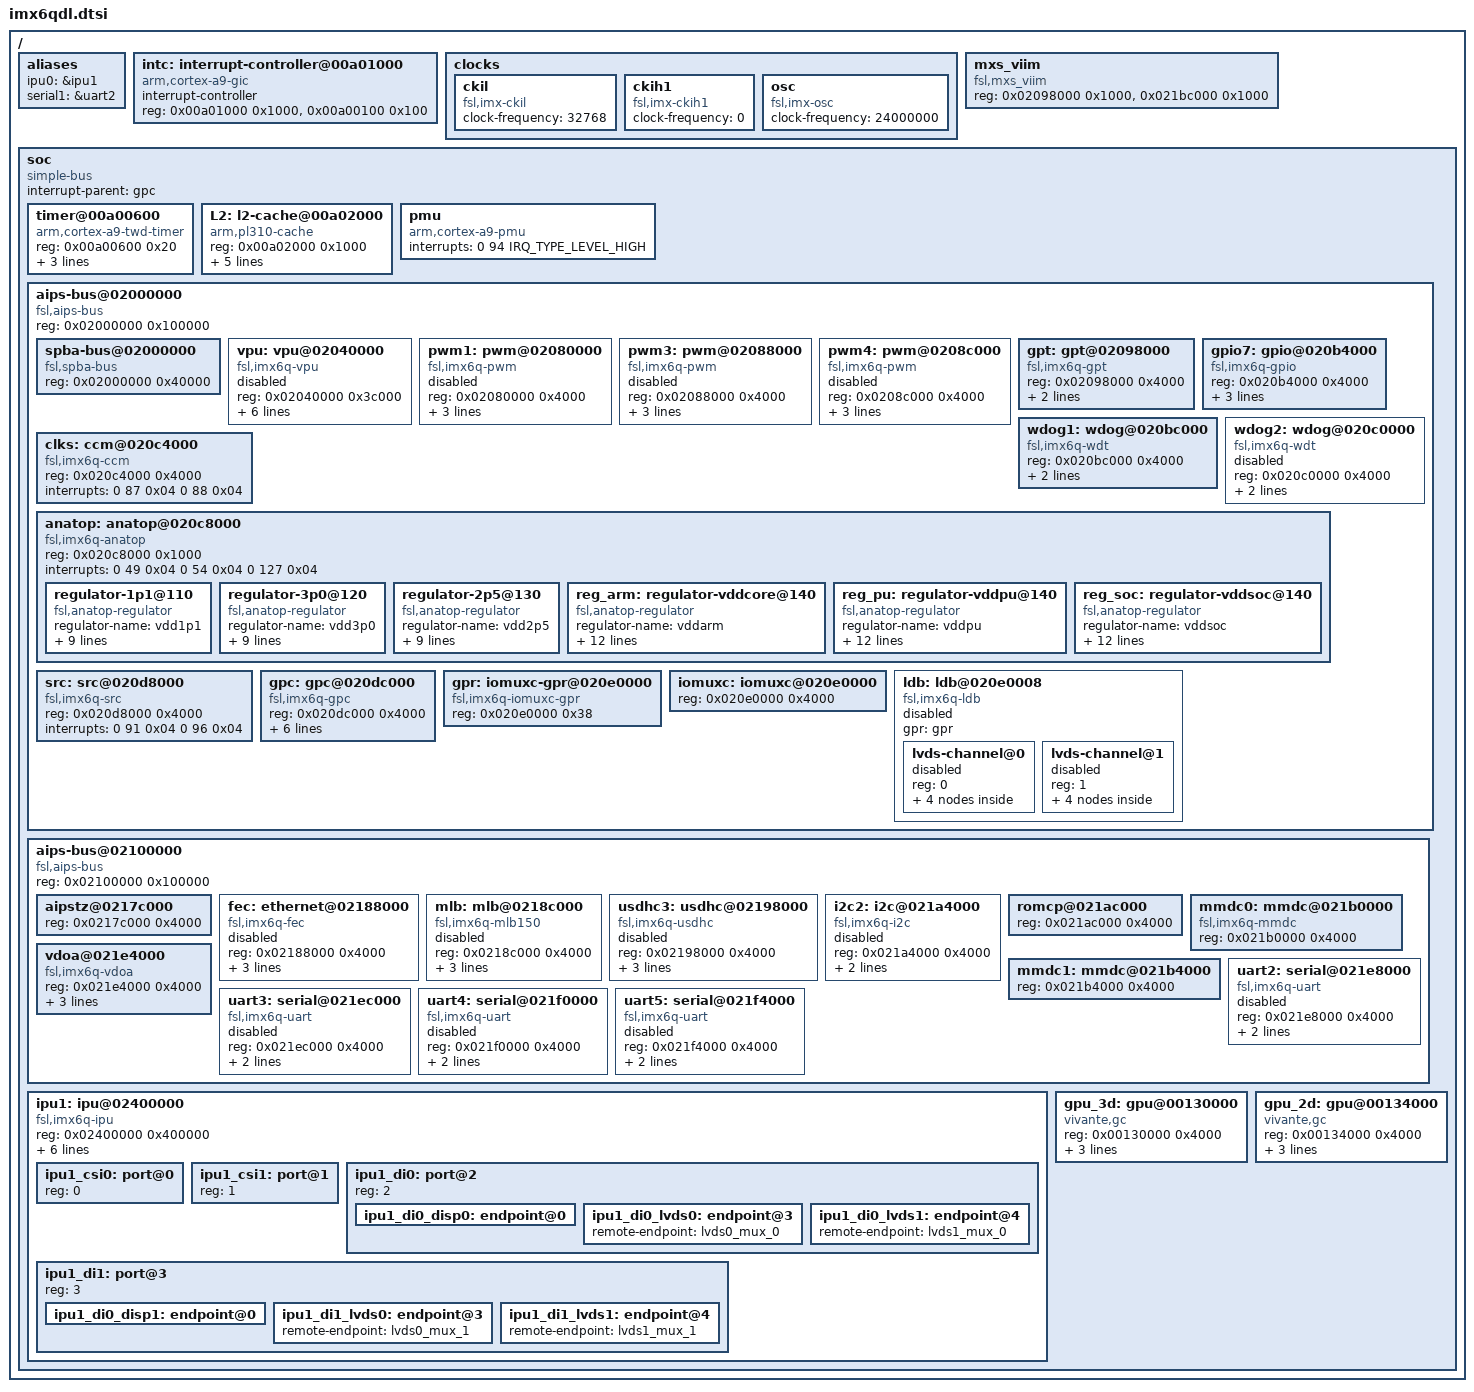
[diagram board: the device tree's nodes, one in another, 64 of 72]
/*
 * Copyright 2011 Freescale Semiconductor, Inc.
 * Copyright 2011 Linaro Ltd.
 *
 * The code contained herein is licensed under the GNU General Public
 * License. You may obtain a copy of the GNU General Public License
 * Version 2 or later at the following locations:
 *
 * http://www.opensource.org/licenses/gpl-license.html
 * http://www.gnu.org/copyleft/gpl.html
 */

#include "skeleton.dtsi"
#include <dt-bindings/gpio/gpio.h>
#include <dt-bindings/interrupt-controller/arm-gic.h>
#include <dt-bindings/clock/imx6qdl-clock.h>

/ {
	aliases {
		/* flexcan0 = &flexcan1; */
		/* flexcan1 = &flexcan2; */
		/* gpio0 = &gpio1; */
		/* gpio1 = &gpio2; */
		/* gpio2 = &gpio3; */
		/* gpio3 = &gpio4; */
		/* gpio4 = &gpio5; */
		/* gpio5 = &gpio6; */
		/* gpio6 = &gpio7; */
		ipu0 = &ipu1;
		/* serial0 = &uart1; */
		serial1 = &uart2;
		/* serial2 = &uart3; */
		/* serial3 = &uart4; */
		/* serial4 = &uart5; */
		/* usbphy0 = &usbphy1; */
		/* usbphy1 = &usbphy2; */
	};

	intc: interrupt-controller@00a01000 {
		compatible = "arm,cortex-a9-gic";
		#interrupt-cells = <3>;
		#address-cells = <1>;
		#size-cells = <1>;
		interrupt-controller;
		reg = <0x00a01000 0x1000>,
		      <0x00a00100 0x100>;
	};

	clocks {
		#address-cells = <1>;
		#size-cells = <0>;

		ckil {
			compatible = "fsl,imx-ckil", "fixed-clock";
			clock-frequency = <32768>;
		};

		ckih1 {
			compatible = "fsl,imx-ckih1", "fixed-clock";
			clock-frequency = <0>;
		};

		osc {
			compatible = "fsl,imx-osc", "fixed-clock";
			clock-frequency = <24000000>;
		};
	};

//	pu_dummy: pudummy_reg {
//		compatible = "fsl,imx6-dummy-pureg"; /* only used in ldo-bypass */
//	};

	mxs_viim {
		compatible = "fsl,mxs_viim";
		reg = <0x02098000 0x1000>, /* GPT base */
		      <0x021bc000 0x1000>; /* OCOTP base */
	};

	soc {
		#address-cells = <1>;
		#size-cells = <1>;
		compatible = "simple-bus";
		interrupt-parent = <&gpc>;
		ranges;

		/* caam_sm: caam-sm@00100000 { */
		/* 	compatible = "fsl,imx6q-caam-sm"; */
		/* 	reg = <0x00100000 0x3fff>; */
		/* }; */

	//	dma_apbh: dma-apbh@00110000 {
	//		compatible = "fsl,imx6q-dma-apbh", "fsl,imx28-dma-apbh";
	//		reg = <0x00110000 0x2000>;
	//		interrupts = <0 13 0x04>, <0 13 0x04>, <0 13 0x04>, <0 13 0x04>;
	//		interrupt-names = "gpmi0", "gpmi1", "gpmi2", "gpmi3";
	//		#dma-cells = <1>;
	//		dma-channels = <4>;
	//		clocks = <&clks 106>;
	//	};

		/* irq_sec_vio: caam_secvio { */
		/* 	compatible = "fsl,imx6q-caam-secvio"; */
		/* 	interrupts = <0 20 0x04>; */
		/* 	secvio_src = <0x8000001d>; */
		/* }; */

		/* gpmi: gpmi-nand@00112000 { */
		/* 	compatible = "fsl,imx6q-gpmi-nand"; */
		/* 	#address-cells = <1>; */
		/* 	#size-cells = <1>; */
		/* 	reg = <0x00112000 0x2000>, <0x00114000 0x2000>; */
		/* 	reg-names = "gpmi-nand", "bch"; */
		/* 	interrupts = <0 15 0x04>; */
		/* 	interrupt-names = "bch"; */
		/* 	clocks = <&clks 152>, <&clks 153>, <&clks 151>, */
		/* 		 <&clks 150>, <&clks 149>; */
		/* 	clock-names = "gpmi_io", "gpmi_apb", "gpmi_bch", */
		/* 		      "gpmi_bch_apb", "per1_bch"; */
		/* 	dmas = <&dma_apbh 0>; */
		/* 	dma-names = "rx-tx"; */
		/* 	status = "disabled"; */
		/* }; */

		timer@00a00600 {
			compatible = "arm,cortex-a9-twd-timer";
			reg = <0x00a00600 0x20>;
			interrupts = <1 13 0xf01>;
			interrupt-parent = <&intc>;
			clocks = <&clks 15>;
		};

		L2: l2-cache@00a02000 {
			compatible = "arm,pl310-cache";
			reg = <0x00a02000 0x1000>;
			interrupts = <0 92 0x04>;
			cache-unified;
			cache-level = <2>;
			arm,tag-latency = <4 2 3>;
			arm,data-latency = <4 2 3>;
		};

		/* pcie: pcie@0x01000000 { */
		/* 	compatible = "fsl,imx6q-pcie", "snps,dw-pcie"; */
		/* 	reg = <0x01ffc000 0x04000>, */
		/* 	      <0x01f00000 0x80000>; */
		/* 	reg-names = "dbi", "config"; */
		/* 	#address-cells = <3>; */
		/* 	#size-cells = <2>; */
		/* 	device_type = "pci"; */
		/* 	ranges = <0x00000800 0 0x01f00000 0x01f00000 0 0x00080000 /\* configuration space *\/ */
		/* 		  0x81000000 0 0          0x01f80000 0 0x00010000 /\* downstream I/O *\/ */
		/* 		  0x82000000 0 0x01000000 0x01000000 0 0x00f00000>; /\* non-prefetchable memory *\/ */
		/* 	num-lanes = <1>; */
		/* 	interrupts = <GIC_SPI 120 IRQ_TYPE_LEVEL_HIGH>; */
		/* 	interrupt-names = "msi"; */
		/* 	#interrupt-cells = <1>; */
		/* 	clocks = <&clks 189>, <&clks 187>, <&clks 144>, <&clks 212>; */
		/* 	clock-names = "pcie_ref_125m", "sata_ref_100m", "pcie_axi", "lvds_gate"; */
		/* 	status = "disabled"; */
		/* }; */

		/* pmu { */
		/* 	compatible = "arm,cortex-a9-pmu"; */
		/* 	interrupts = <0 94 0x04>; */
		/* }; */
		pmu {
			compatible = "arm,cortex-a9-pmu";
			interrupts = <0 94 IRQ_TYPE_LEVEL_HIGH>;
		};

		aips-bus@02000000 { /* AIPS1 */
			compatible = "fsl,aips-bus", "simple-bus";
			#address-cells = <1>;
			#size-cells = <1>;
			reg = <0x02000000 0x100000>;
			ranges;

			spba-bus@02000000 {
				compatible = "fsl,spba-bus", "simple-bus";
				#address-cells = <1>;
				#size-cells = <1>;
				reg = <0x02000000 0x40000>;
				ranges;

				/* spdif: spdif@02004000 { */
				/* 	compatible = "fsl,imx6q-spdif", */
				/* 		"fsl,imx35-spdif"; */
				/* 	reg = <0x02004000 0x4000>; */
				/* 	interrupts = <0 52 0x04>; */
				/* 	dmas = <&sdma 14 18 0>, */
				/* 	       <&sdma 15 18 0>; */
				/* 	dma-names = "rx", "tx"; */
				/* 	clocks = <&clks 197>, <&clks 3>, */
				/* 	       <&clks 197>, <&clks 107>, */
				/* 	       <&clks 0>, <&clks 118>, */
				/* 	       <&clks 62>, <&clks 139>, */
				/* 	       <&clks 0>, <&clks 156>; */
				/* 	clock-names = "core", "rxtx0", */
				/* 		"rxtx1", "rxtx2", */
				/* 		"rxtx3", "rxtx4", */
				/* 		"rxtx5", "rxtx6", */
				/* 		"rxtx7", "dma"; */
				/* 	status = "disabled"; */
				/* }; */

				/* ecspi1: ecspi@02008000 { */
				/* 	#address-cells = <1>; */
				/* 	#size-cells = <0>; */
				/* 	compatible = "fsl,imx6q-ecspi", "fsl,imx51-ecspi"; */
				/* 	reg = <0x02008000 0x4000>; */
				/* 	interrupts = <0 31 0x04>; */
				/* 	clocks = <&clks 112>, <&clks 112>; */
				/* 	clock-names = "ipg", "per"; */
				/* 	status = "disabled"; */
				/* }; */

				/* ecspi2: ecspi@0200c000 { */
				/* 	#address-cells = <1>; */
				/* 	#size-cells = <0>; */
				/* 	compatible = "fsl,imx6q-ecspi", "fsl,imx51-ecspi"; */
				/* 	reg = <0x0200c000 0x4000>; */
				/* 	interrupts = <0 32 0x04>; */
				/* 	clocks = <&clks 113>, <&clks 113>; */
				/* 	clock-names = "ipg", "per"; */
				/* 	status = "disabled"; */
				/* }; */

				/* ecspi3: ecspi@02010000 { */
				/* 	#address-cells = <1>; */
				/* 	#size-cells = <0>; */
				/* 	compatible = "fsl,imx6q-ecspi", "fsl,imx51-ecspi"; */
				/* 	reg = <0x02010000 0x4000>; */
				/* 	interrupts = <0 33 0x04>; */
				/* 	clocks = <&clks 114>, <&clks 114>; */
				/* 	clock-names = "ipg", "per"; */
				/* 	status = "disabled"; */
				/* }; */

				/* ecspi4: ecspi@02014000 { */
				/* 	#address-cells = <1>; */
				/* 	#size-cells = <0>; */
				/* 	compatible = "fsl,imx6q-ecspi", "fsl,imx51-ecspi"; */
				/* 	reg = <0x02014000 0x4000>; */
				/* 	interrupts = <0 34 0x04>; */
				/* 	clocks = <&clks 115>, <&clks 115>; */
				/* 	clock-names = "ipg", "per"; */
				/* 	status = "disabled"; */
				/* }; */

				/* uart1: serial@02020000 { */
				/* 	compatible = "fsl,imx6q-uart", "fsl,imx21-uart"; */
				/* 	reg = <0x02020000 0x4000>; */
				/* 	interrupts = <0 26 0x04>; */
				/* 	clocks = <&clks 160>, <&clks 161>; */
				/* 	clock-names = "ipg", "per"; */
				/* 	dmas = <&sdma 25 4 0>, <&sdma 26 4 0>; */
				/* 	dma-names = "rx", "tx"; */
				/* 	status = "disabled"; */
				/* }; */

				/* esai: esai@02024000 { */
				/* 	compatible = "fsl,imx6q-esai"; */
				/* 	reg = <0x02024000 0x4000>; */
				/* 	interrupts = <0 51 0x04>; */
				/* 	clocks = <&clks 118>, <&clks 156>; */
				/* 	clock-names = "core", "dma"; */
				/* 	fsl,esai-dma-events = <24 23>; */
				/* 	fsl,flags = <1>; */
				/* 	status = "disabled"; */
				/* }; */

				/* ssi1: ssi@02028000 { */
				/* 	compatible = "fsl,imx6q-ssi","fsl,imx21-ssi"; */
				/* 	reg = <0x02028000 0x4000>; */
				/* 	interrupts = <0 46 0x04>; */
				/* 	clocks = <&clks 178>, <&clks 157>; */
				/* 	clock-names = "ipg", "baud"; */
				/* 	dmas = <&sdma 37 1 0>, */
				/* 	       <&sdma 38 1 0>; */
				/* 	dma-names = "rx", "tx"; */
				/* 	status = "disabled"; */
				/* }; */

				/* ssi2: ssi@0202c000 { */
				/* 	compatible = "fsl,imx6q-ssi","fsl,imx21-ssi"; */
				/* 	reg = <0x0202c000 0x4000>; */
				/* 	interrupts = <0 47 0x04>; */
				/* 	clocks = <&clks 179>, <&clks 158>; */
				/* 	clock-names = "ipg", "baud"; */
				/* 	dmas = <&sdma 41 1 0>, */
				/* 	       <&sdma 42 1 0>; */
				/* 	dma-names = "rx", "tx"; */
				/* 	status = "disabled"; */
				/* }; */

				/* ssi3: ssi@02030000 { */
				/* 	compatible = "fsl,imx6q-ssi","fsl,imx21-ssi"; */
				/* 	reg = <0x02030000 0x4000>; */
				/* 	interrupts = <0 48 0x04>; */
				/* 	clocks = <&clks 180>, <&clks 159>; */
				/* 	clock-names = "ipg", "baud"; */
				/* 	dmas = <&sdma 45 1 0>, */
				/* 	       <&sdma 46 1 0>; */
				/* 	dma-names = "rx", "tx"; */
				/* 	status = "disabled"; */
				/* }; */


		//		asrc: asrc@02034000 {
		//			compatible = "fsl,imx53-asrc";
		//			reg = <0x02034000 0x4000>;
		//			interrupts = <0 50 0x4>;
		//			clocks = <&clks 210>, /* IMX6QDL_CLK_ASRC_IPG */
		//				<&clks 211>, /* IMX6QDL_CLK_ASRC_MEM */
		//				<&clks 0>,
		//				<&clks 0>, <&clks 0>, <&clks 0>, <&clks 0>,
		//				<&clks 0>, <&clks 0>, <&clks 0>, <&clks 0>,
		//				<&clks 0>, <&clks 0>, <&clks 0>, <&clks 0>,
		//				<&clks 107>, /* IMX6QDL_CLK_ASRC */
		//				<&clks 0>, <&clks 0>,
		//				<&clks 156>; /* IMX6QDL_CLK_SPBA */
		//			clock-names = "mem", "ipg", "asrck_0",
		//				"asrck_1", "asrck_2", "asrck_3", "asrck_4",
		//				"asrck_5", "asrck_6", "asrck_7", "asrck_8",
		//				"asrck_9", "asrck_a", "asrck_b", "asrck_c",
		//				"asrck_d", "asrck_e", "asrck_f", "spba";
		//			dmas = <&sdma 17 23 1>, <&sdma 18 23 1>, <&sdma 19 23 1>,
		//				<&sdma 20 23 1>, <&sdma 21 23 1>, <&sdma 22 23 1>;
		//			dma-names = "rxa", "rxb", "rxc",
		//					"txa", "txb", "txc";
		//			fsl,asrc-rate  = <48000>;
		//			fsl,asrc-width = <16>;
		//			status = "okay";
		//		};

				/* asrc_p2p: asrc_p2p { */
				/* 	compatible = "fsl,imx6q-asrc-p2p"; */
				/* 	fsl,output-rate  = <48000>; */
				/* 	fsl,output-width = <16>; */
				/* 	fsl,asrc-dma-rx-events = <17 18 19>; */
				/* 	fsl,asrc-dma-tx-events = <20 21 22>; */
				/* 	status = "okay"; */
				/* }; */

				/* spba@0203c000 { */
				/* 	reg = <0x0203c000 0x4000>; */
				/* }; */
			};

			vpu: vpu@02040000 {
				compatible = "fsl,imx6q-vpu";
				reg = <0x02040000 0x3c000>;
				reg-names = "vpu_regs";
				interrupts = <0 3 0x04>, <0 12 0x04>;
				interrupt-names = "vpu_jpu_irq", "vpu_ipi_irq";
				clocks = <&clks 168>, <&clks 140>, <&clks 142>;
				clock-names = "vpu_clk", "mmdc_ch0_axi", "ocram";
				iramsize = <0x21000>;
				iram = <&ocram>;
				resets = <&src 1>;
				pu-supply = <&reg_pu>;
				status = "disabled";
			};

			/* aipstz@0207c000 { /\* AIPSTZ1 *\/ */
			/* 	reg = <0x0207c000 0x4000>; */
			/* }; */

			pwm1: pwm@02080000 {
				#pwm-cells = <2>;
				compatible = "fsl,imx6q-pwm", "fsl,imx27-pwm";
				reg = <0x02080000 0x4000>;
				interrupts = <0 83 IRQ_TYPE_LEVEL_HIGH>;
				clocks = <&clks IMX6QDL_CLK_IPG>,
					 <&clks IMX6QDL_CLK_PWM1>;
				clock-names = "ipg", "per";
				status = "disabled";
			};

			/* pwm2: pwm@02084000 { */
			/* 	#pwm-cells = <2>; */
			/* 	compatible = "fsl,imx6q-pwm", "fsl,imx27-pwm"; */
			/* 	reg = <0x02084000 0x4000>; */
			/* 	interrupts = <0 84 0x04>; */
			/* 	clocks = <&clks 62>, <&clks 146>; */
			/* 	clock-names = "ipg", "per"; */
			/* }; */

			pwm3: pwm@02088000 {
				#pwm-cells = <2>;
				compatible = "fsl,imx6q-pwm", "fsl,imx27-pwm";
				reg = <0x02088000 0x4000>;
				interrupts = <0 85 IRQ_TYPE_LEVEL_HIGH>;
				clocks = <&clks IMX6QDL_CLK_IPG>,
					 <&clks IMX6QDL_CLK_PWM3>;
				clock-names = "ipg", "per";
				status = "disabled";
			};

			pwm4: pwm@0208c000 {
				#pwm-cells = <2>;
				compatible = "fsl,imx6q-pwm", "fsl,imx27-pwm";
				reg = <0x0208c000 0x4000>;
				interrupts = <0 86 IRQ_TYPE_LEVEL_HIGH>;
				clocks = <&clks IMX6QDL_CLK_IPG>,
					 <&clks IMX6QDL_CLK_PWM4>;
				clock-names = "ipg", "per";
				status = "disabled";
			};

			gpt: gpt@02098000 {
				compatible = "fsl,imx6q-gpt", "fsl,imx31-gpt";
				reg = <0x02098000 0x4000>;

				interrupts = <0 55 0x04>;


				clocks = <&clks 119>, /* IMX6QDL_CLK_GPT_IPG */
					 <&clks 120>, /* IMX6QDL_CLK_GPT_IPG_PER */
					 <&clks 237>; /* IMX6QDL_CLK_GPT_3M */
				clock-names = "ipg", "per", "osc_per";
			};

			/* gpio1: gpio@0209c000 { */
			/* 	compatible = "fsl,imx6q-gpio", "fsl,imx35-gpio"; */
			/* 	reg = <0x0209c000 0x4000>; */
			/* 	interrupts = <0 66 0x04 0 67 0x04>; */
			/* 	gpio-controller; */
			/* 	#gpio-cells = <2>; */
			/* 	interrupt-controller; */
			/* 	#interrupt-cells = <2>; */
			/* }; */

			/* gpio2: gpio@020a0000 { */
			/* 	compatible = "fsl,imx6q-gpio", "fsl,imx35-gpio"; */
			/* 	reg = <0x020a0000 0x4000>; */
			/* 	interrupts = <0 68 0x04 0 69 0x04>; */
			/* 	gpio-controller; */
			/* 	#gpio-cells = <2>; */
			/* 	interrupt-controller; */
			/* 	#interrupt-cells = <2>; */
			/* }; */

			/* gpio3: gpio@020a4000 { */
			/* 	compatible = "fsl,imx6q-gpio", "fsl,imx35-gpio"; */
			/* 	reg = <0x020a4000 0x4000>; */
			/* 	interrupts = <0 70 0x04 0 71 0x04>; */
			/* 	gpio-controller; */
			/* 	#gpio-cells = <2>; */
			/* 	interrupt-controller; */
			/* 	#interrupt-cells = <2>; */
			/* }; */

			/* gpio4: gpio@020a8000 { */
			/* 	compatible = "fsl,imx6q-gpio", "fsl,imx35-gpio"; */
			/* 	reg = <0x020a8000 0x4000>; */
			/* 	interrupts = <0 72 0x04 0 73 0x04>; */
			/* 	gpio-controller; */
			/* 	#gpio-cells = <2>; */
			/* 	interrupt-controller; */
			/* 	#interrupt-cells = <2>; */
			/* }; */

			/* gpio5: gpio@020ac000 { */
			/* 	compatible = "fsl,imx6q-gpio", "fsl,imx35-gpio"; */
			/* 	reg = <0x020ac000 0x4000>; */
			/* 	interrupts = <0 74 0x04 0 75 0x04>; */
			/* 	gpio-controller; */
			/* 	#gpio-cells = <2>; */
			/* 	interrupt-controller; */
			/* 	#interrupt-cells = <2>; */
			/* }; */

			/* gpio6: gpio@020b0000 { */
			/* 	compatible = "fsl,imx6q-gpio", "fsl,imx35-gpio"; */
			/* 	reg = <0x020b0000 0x4000>; */
			/* 	interrupts = <0 76 0x04 0 77 0x04>; */
			/* 	gpio-controller; */
			/* 	#gpio-cells = <2>; */
			/* 	interrupt-controller; */
			/* 	#interrupt-cells = <2>; */
			/* }; */

			gpio7: gpio@020b4000 {
				compatible = "fsl,imx6q-gpio", "fsl,imx35-gpio";
				reg = <0x020b4000 0x4000>;
				interrupts = <0 78 0x04 0 79 0x04>;
				gpio-controller;
				#gpio-cells = <2>;
				interrupt-controller;
				#interrupt-cells = <2>;
			};

			/* kpp: kpp@020b8000 { */
			/* 	reg = <0x020b8000 0x4000>; */
			/* 	interrupts = <0 82 0x04>; */
			/* }; */

			wdog1: wdog@020bc000 {
				compatible = "fsl,imx6q-wdt", "fsl,imx21-wdt";
				reg = <0x020bc000 0x4000>;
				interrupts = <0 80 0x04>;
				clocks = <&clks 0>;
			};

			wdog2: wdog@020c0000 {
				compatible = "fsl,imx6q-wdt", "fsl,imx21-wdt";
				reg = <0x020c0000 0x4000>;
				interrupts = <0 81 0x04>;
				clocks = <&clks 0>;
				status = "disabled";
			};

			clks: ccm@020c4000 {
				compatible = "fsl,imx6q-ccm";
				reg = <0x020c4000 0x4000>;
				interrupts = <0 87 0x04 0 88 0x04>;
				#clock-cells = <1>;
			};

			anatop: anatop@020c8000 {
				compatible = "fsl,imx6q-anatop", "syscon", "simple-bus";
				reg = <0x020c8000 0x1000>;
				interrupts = <0 49 0x04 0 54 0x04 0 127 0x04>;

				regulator-1p1@110 {
					compatible = "fsl,anatop-regulator";
					regulator-name = "vdd1p1";
					regulator-min-microvolt = <800000>;
					regulator-max-microvolt = <1375000>;
					regulator-always-on;
					anatop-reg-offset = <0x110>;
					anatop-vol-bit-shift = <8>;
					anatop-vol-bit-width = <5>;
					anatop-min-bit-val = <4>;
					anatop-min-voltage = <800000>;
					anatop-max-voltage = <1375000>;
				};

				regulator-3p0@120 {
					compatible = "fsl,anatop-regulator";
					regulator-name = "vdd3p0";
					regulator-min-microvolt = <2800000>;
					regulator-max-microvolt = <3150000>;
					regulator-always-on;
					anatop-reg-offset = <0x120>;
					anatop-vol-bit-shift = <8>;
					anatop-vol-bit-width = <5>;
					anatop-min-bit-val = <0>;
					anatop-min-voltage = <2625000>;
					anatop-max-voltage = <3400000>;
				};

				regulator-2p5@130 {
					compatible = "fsl,anatop-regulator";
					regulator-name = "vdd2p5";
					regulator-min-microvolt = <2000000>;
					regulator-max-microvolt = <2750000>;
					regulator-always-on;
					anatop-reg-offset = <0x130>;
					anatop-vol-bit-shift = <8>;
					anatop-vol-bit-width = <5>;
					anatop-min-bit-val = <0>;
					anatop-min-voltage = <2000000>;
					anatop-max-voltage = <2750000>;
				};

				reg_arm: regulator-vddcore@140 {
					compatible = "fsl,anatop-regulator";
					regulator-name = "vddarm";
					regulator-min-microvolt = <725000>;
					regulator-max-microvolt = <1450000>;
					regulator-always-on;
					anatop-reg-offset = <0x140>;
					anatop-vol-bit-shift = <0>;
					anatop-vol-bit-width = <5>;
					anatop-delay-reg-offset = <0x170>;
					anatop-delay-bit-shift = <24>;
					anatop-delay-bit-width = <2>;
					anatop-min-bit-val = <1>;
					anatop-min-voltage = <725000>;
					anatop-max-voltage = <1450000>;
				};

				reg_pu: regulator-vddpu@140 {
					compatible = "fsl,anatop-regulator";
					regulator-name = "vddpu";
					regulator-min-microvolt = <725000>;
					regulator-max-microvolt = <1450000>;
					regulator-enable-ramp-delay = <150>;
					anatop-reg-offset = <0x140>;
					anatop-vol-bit-shift = <9>;
					anatop-vol-bit-width = <5>;
					anatop-delay-reg-offset = <0x170>;
					anatop-delay-bit-shift = <26>;
					anatop-delay-bit-width = <2>;
					anatop-min-bit-val = <1>;
					anatop-min-voltage = <725000>;
					anatop-max-voltage = <1450000>;
				};

				reg_soc: regulator-vddsoc@140 {
					compatible = "fsl,anatop-regulator";
					regulator-name = "vddsoc";
					regulator-min-microvolt = <725000>;
					regulator-max-microvolt = <1450000>;
					regulator-always-on;
					anatop-reg-offset = <0x140>;
					anatop-vol-bit-shift = <18>;
					anatop-vol-bit-width = <5>;
					anatop-delay-reg-offset = <0x170>;
					anatop-delay-bit-shift = <28>;
					anatop-delay-bit-width = <2>;
					anatop-min-bit-val = <1>;
					anatop-min-voltage = <725000>;
					anatop-max-voltage = <1450000>;
				};
			};

			src: src@020d8000 {
				compatible = "fsl,imx6q-src", "fsl,imx51-src";
				reg = <0x020d8000 0x4000>;
				interrupts = <0 91 0x04 0 96 0x04>;
				#reset-cells = <1>;
			};

			gpc: gpc@020dc000 {
				compatible = "fsl,imx6q-gpc";
				reg = <0x020dc000 0x4000>;
				interrupts = <0 89 0x04 0 90 0x04>;
				interrupt-controller;
				#interrupt-cells = <3>;
				interrupt-parent = <&intc>;
				clocks = <&clks 122>, /* IMX6QDL_CLK_GPU3D_CORE */
					 <&clks  74>, /* IMX6QDL_CLK_GPU3D_SHADER */
					 <&clks 121>, /* IMX6QDL_CLK_GPU2D_CORE */
					 <&clks  26>, /* IMX6QDL_CLK_GPU2D_AXI */
					 <&clks 143>, /* IMX6QDL_CLK_OPENVG_AXI */
					 <&clks 168>; /* IMX6QDL_CLK_VPU_AXI */
				pu-supply = <&reg_pu>;
				#power-domain-cells = <1>;
			};

			gpr: iomuxc-gpr@020e0000 {
				compatible = "fsl,imx6q-iomuxc-gpr", "syscon";
				reg = <0x020e0000 0x38>;
			};

			iomuxc: iomuxc@020e0000 {
				reg = <0x020e0000 0x4000>;
			};

			ldb: ldb@020e0008 {
				#address-cells = <1>;
				#size-cells = <0>;
				compatible = "fsl,imx6q-ldb", "fsl,imx53-ldb";
				gpr = <&gpr>;
				status = "disabled";

				lvds-channel@0 {
					#address-cells = <1>;
					#size-cells = <0>;
					reg = <0>;
					status = "disabled";

					port@0 {
						reg = <0>;

						lvds0_mux_0: endpoint {
							remote-endpoint = <&ipu1_di0_lvds0>;
						};
					};

					port@1 {
						reg = <1>;

						lvds0_mux_1: endpoint {
							remote-endpoint = <&ipu1_di1_lvds0>;
						};
					};
				};

				lvds-channel@1 {
					#address-cells = <1>;
					#size-cells = <0>;
					reg = <1>;
					status = "disabled";

					port@0 {
						reg = <0>;

						lvds1_mux_0: endpoint {
							remote-endpoint = <&ipu1_di0_lvds1>;
						};
					};

					port@1 {
						reg = <1>;

						lvds1_mux_1: endpoint {
							remote-endpoint = <&ipu1_di1_lvds1>;
						};
					};
				};
			};

//			sdma: sdma@020ec000 {
//				compatible = "fsl,imx6q-sdma", "fsl,imx35-sdma";
//				reg = <0x020ec000 0x4000>;
//				interrupts = <0 2 0x04>;
//				clocks = <&clks 155>, <&clks 155>;
//				clock-names = "ipg", "ahb";
//				#dma-cells = <3>;
//				fsl,sdma-ram-script-name = "imx/sdma/sdma-imx6q.bin";
//			};
		};

		aips-bus@02100000 { /* AIPS2 */
			compatible = "fsl,aips-bus", "simple-bus";
			#address-cells = <1>;
			#size-cells = <1>;
			reg = <0x02100000 0x100000>;
			ranges;

			aipstz@0217c000 { /* AIPSTZ2 */
				reg = <0x0217c000 0x4000>;
			};

			fec: ethernet@02188000 {
				compatible = "fsl,imx6q-fec";
				reg = <0x02188000 0x4000>;
				interrupts-extended = <&intc 0 118 0x04>,
						      <&intc 0 119 0x04>;
				clocks = <&clks 117>, <&clks 117>, <&clks 190>;
				clock-names = "ipg", "ahb", "ptp";
				status = "disabled";
			};

			mlb: mlb@0218c000 {
				compatible = "fsl,imx6q-mlb150";
				reg = <0x0218c000 0x4000>;
				interrupts = <0 53 0x04 0 117 0x04 0 126 0x04>;
				clocks = <&clks 139>, <&clks 175>;
				clock-names = "mlb", "pll8_mlb";
				iram = <&ocram>;
				status = "disabled";
			};

			usdhc3: usdhc@02198000 {
				compatible = "fsl,imx6q-usdhc";
				reg = <0x02198000 0x4000>;
				interrupts = <0 24 0x04>;
				clocks = <&clks 165>, <&clks 165>, <&clks 165>;
				clock-names = "ipg", "ahb", "per";
				bus-width = <4>;
				status = "disabled";
			};

			i2c2: i2c@021a4000 {
				#address-cells = <1>;
				#size-cells = <0>;
				compatible = "fsl,imx6q-i2c", "fsl,imx21-i2c";
				reg = <0x021a4000 0x4000>;
				interrupts = <0 37 IRQ_TYPE_LEVEL_HIGH>;
				clocks = <&clks IMX6QDL_CLK_I2C2>;
				status = "disabled";
			};


			/* i2c3: i2c@021a8000 { */
			/* 	#address-cells = <1>; */
			/* 	#size-cells = <0>; */
			/* 	compatible = "fsl,imx6q-i2c", "fsl,imx21-i2c"; */
			/* 	reg = <0x021a8000 0x4000>; */
			/* 	interrupts = <0 38 0x04>; */
			/* 	clocks = <&clks 127>; */
			/* 	status = "disabled"; */
			/* }; */

			romcp@021ac000 {
				reg = <0x021ac000 0x4000>;
			};

			mmdc0: mmdc@021b0000 { /* MMDC0 */
				compatible = "fsl,imx6q-mmdc";
				reg = <0x021b0000 0x4000>;
			};

			mmdc1: mmdc@021b4000 { /* MMDC1 */
				reg = <0x021b4000 0x4000>;
			};

			vdoa@021e4000 {
				compatible = "fsl,imx6q-vdoa";
				reg = <0x021e4000 0x4000>;
				interrupts = <0 18 0x04>;
				clocks = <&clks 202>;
				iram = <&ocram>;
			};

			uart2: serial@021e8000 {
				compatible = "fsl,imx6q-uart", "fsl,imx21-uart";
				reg = <0x021e8000 0x4000>;
				interrupts = <0 27 0x04>;
				clocks = <&clks 160>, <&clks 161>;
				clock-names = "ipg", "per";
	//			dmas = <&sdma 27 4 0>, <&sdma 28 4 0>;
				dma-names = "rx", "tx";
				status = "disabled";
			};

			uart3: serial@021ec000 {
				compatible = "fsl,imx6q-uart", "fsl,imx21-uart";
				reg = <0x021ec000 0x4000>;
				interrupts = <0 28 0x04>;
				clocks = <&clks 160>, <&clks 161>;
				clock-names = "ipg", "per";
	//			dmas = <&sdma 29 4 0>, <&sdma 30 4 0>;
				dma-names = "rx", "tx";
				status = "disabled";
			};

			uart4: serial@021f0000 {
				compatible = "fsl,imx6q-uart", "fsl,imx21-uart";
				reg = <0x021f0000 0x4000>;
				interrupts = <0 29 0x04>;
				clocks = <&clks 160>, <&clks 161>;
				clock-names = "ipg", "per";
//				dmas = <&sdma 31 4 0>, <&sdma 32 4 0>;
				dma-names = "rx", "tx";
				status = "disabled";
			};

			uart5: serial@021f4000 {
				compatible = "fsl,imx6q-uart", "fsl,imx21-uart";
				reg = <0x021f4000 0x4000>;
				interrupts = <0 30 0x04>;
				clocks = <&clks 160>, <&clks 161>;
				clock-names = "ipg", "per";
//				dmas = <&sdma 33 4 0>, <&sdma 34 4 0>;
				dma-names = "rx", "tx";
				status = "disabled";
			};
		};

		ipu1: ipu@02400000 {
			#address-cells = <1>;
			#size-cells = <0>;
			compatible = "fsl,imx6q-ipu";
			reg = <0x02400000 0x400000>;
			interrupts = <
				0   6 0x4 /* ignore */
				0   5 0x4 /* ignore */
				0  97 0x4 /* 129: EOF_EN_28  --  irq_a */
				0  98 0x4 /* 130: EOF_EN_23  --  irq_b */
				0 113 0x4 /* 145: DC_FC_1    --  irq_c */
				0 114 0x4 /* 146: DP_SF_EN   --  irq_d */
			>;
			clocks = <&clks IMX6QDL_CLK_IPU1>,
				 <&clks IMX6QDL_CLK_IPU1_DI0>,
				 <&clks IMX6QDL_CLK_IPU1_DI1>;
			clock-names = "bus", "di0", "di1";
			resets = <&src 2>;

			ipu1_csi0: port@0 {
				reg = <0>;
			};

			ipu1_csi1: port@1 {
				reg = <1>;
			};

			ipu1_di0: port@2 {
				#address-cells = <1>;
				#size-cells = <0>;
				reg = <2>;

				ipu1_di0_disp0: endpoint@0 {
				};

				//ipu1_di0_hdmi: endpoint@1 {
				//	remote-endpoint = <&hdmi_mux_0>;
				//};

				//ipu1_di0_mipi: endpoint@2 {
				//	remote-endpoint = <&mipi_mux_0>;
				//};

				ipu1_di0_lvds0: endpoint@3 {
					remote-endpoint = <&lvds0_mux_0>;
				};

				ipu1_di0_lvds1: endpoint@4 {
					remote-endpoint = <&lvds1_mux_0>;
				};
			};

			ipu1_di1: port@3 {
				#address-cells = <1>;
				#size-cells = <0>;
				reg = <3>;

				ipu1_di0_disp1: endpoint@0 {
				};

				//ipu1_di1_hdmi: endpoint@1 {
				//	remote-endpoint = <&hdmi_mux_1>;
				//};

				//ipu1_di1_mipi: endpoint@2 {
				//	remote-endpoint = <&mipi_mux_1>;
				//};

				ipu1_di1_lvds0: endpoint@3 {
					remote-endpoint = <&lvds0_mux_1>;
				};

				ipu1_di1_lvds1: endpoint@4 {
					remote-endpoint = <&lvds1_mux_1>;
				};
			};
		};

		gpu_3d: gpu@00130000 {
			compatible = "vivante,gc";
			reg = <0x00130000 0x4000>;
			interrupts = <0 9 IRQ_TYPE_LEVEL_HIGH>;
			clocks = <&clks 27>, /* IMX6QDL_CLK_GPU3D_AXI */
				 <&clks 122>, /* IMX6QDL_CLK_GPU3D_CORE */
				 <&clks 74>; /* IMX6QDL_CLK_GPU3D_SHADER */
			clock-names = "bus", "core", "shader";
			power-domains = <&gpc 1>;
		};

		gpu_2d: gpu@00134000 {
			compatible = "vivante,gc";
			reg = <0x00134000 0x4000>;
			interrupts = <0 10 IRQ_TYPE_LEVEL_HIGH>;
			clocks = <&clks 26>, /* IMX6QDL_CLK_GPU2D_AXI */
				 <&clks 121>; /* IMX6QDL_CLK_GPU2D_CORE */
			clock-names = "bus", "core";
			power-domains = <&gpc 1>;
		};
	};
};
